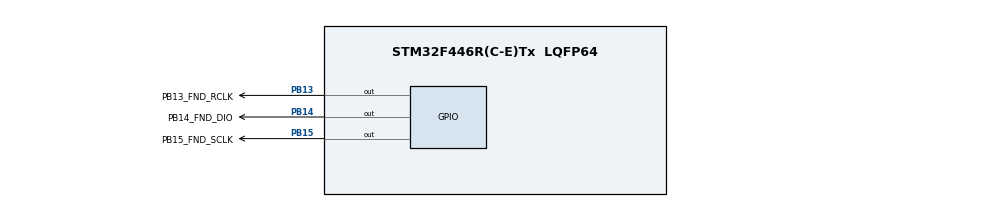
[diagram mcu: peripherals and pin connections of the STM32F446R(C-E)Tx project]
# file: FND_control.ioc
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Mcu.Family=STM32F4
Mcu.Name=STM32F446R(C-E)Tx
Mcu.Package=LQFP64
NVIC.PriorityGroup=NVIC_PRIORITYGROUP_4
PB13.GPIO_Label=PB13_FND_RCLK
PB13.GPIO_ModeDefaultOutputPP=GPIO_MODE_OUTPUT_PP
PB13.GPIO_PuPd=GPIO_PULLUP
PB13.GPIO_Speed=GPIO_SPEED_FREQ_HIGH
PB13.PinState=GPIO_PIN_SET
PB13.Signal=GPIO_Output
PB14.GPIO_Label=PB14_FND_DIO
PB14.GPIO_ModeDefaultOutputPP=GPIO_MODE_OUTPUT_PP
PB14.GPIO_PuPd=GPIO_PULLUP
PB14.GPIO_Speed=GPIO_SPEED_FREQ_HIGH
PB14.PinState=GPIO_PIN_SET
PB14.Signal=GPIO_Output
PB15.GPIO_Label=PB15_FND_SCLK
PB15.GPIO_ModeDefaultOutputPP=GPIO_MODE_OUTPUT_PP
PB15.GPIO_PuPd=GPIO_PULLUP
PB15.GPIO_Speed=GPIO_SPEED_FREQ_HIGH
PB15.PinState=GPIO_PIN_SET
PB15.Signal=GPIO_Output
ProjectManager.HeapSize=0x200
ProjectManager.StackSize=0x400
ProjectManager.TargetToolchain=STM32CubeIDE
RCC.CortexFreq_Value=16000000
RCC.USBFreq_Value=96000000
RCC.VCOOutputFreq_Value=192000000
board=custom

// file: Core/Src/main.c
/* USER CODE BEGIN Header */
/**
  ******************************************************************************
  * @file           : main.c
  * @brief          : Main program body
  ******************************************************************************
  * @attention
  *
  * Copyright (c) 2026 STMicroelectronics.
  * All rights reserved.
  *
  * This software is licensed under terms that can be found in the LICENSE file
  * in the root directory of this software component.
  * If no LICENSE file comes with this software, it is provided AS-IS.
  *
  ******************************************************************************
  */
/* USER CODE END Header */
#include "main.h"

/* USER CODE BEGIN Includes */
#include "FND_controller.h"
/* USER CODE END Includes */

void SystemClock_Config(void);
static void MX_GPIO_Init(void);

int main(void)
{

  /* MCU Configuration--------------------------------------------------------*/

  /* Reset of all peripherals, Initializes the Flash interface and the Systick. */
  HAL_Init();

  /* USER CODE BEGIN Init */

  init_FND();

  /* USER CODE END Init */

  /* Configure the system clock */
  SystemClock_Config();

  /* Initialize all configured peripherals */
  MX_GPIO_Init();

  /* Infinite loop */
  /* USER CODE BEGIN WHILE */
  while (1)
  {
	  // digit2 함수를 이용하여 0부터 99까지 출력
	  /*
	  for (int i = 0; i <= 99; i++)
	  {
		  digit2(i, 0b0001, 50);
	  }
	  */

	  // digit4_replay 함수를 이용하여 0부터 9999까지 출력

	  for (int i = 0; i <= 9999; i++)
	  {
		  //digit4ShowZero_replay(i, 50);
		  digit4_temper(i, 50);
	  }

	  // send_port 함수를 이용하여 GPIO 문자 직접 출력
	  /*
	  send_port(0xC2, 0b1000);
	  send_port(0x8C, 0b0100);
	  send_port(0xF9, 0b0010);
	  send_port(0xC0, 0b0001);
	  */

    /* USER CODE END WHILE */

  }
}

void SystemClock_Config(void)
{
  RCC_OscInitTypeDef RCC_OscInitStruct = {0};
  RCC_ClkInitTypeDef RCC_ClkInitStruct = {0};

  /** Configure the main internal regulator output voltage
  */
  __HAL_RCC_PWR_CLK_ENABLE();
  __HAL_PWR_VOLTAGESCALING_CONFIG(PWR_REGULATOR_VOLTAGE_SCALE3);

  /** Initializes the RCC Oscillators according to the specified parameters
  * in the RCC_OscInitTypeDef structure.
  */
  RCC_OscInitStruct.OscillatorType = RCC_OSCILLATORTYPE_HSI;
  RCC_OscInitStruct.HSIState = RCC_HSI_ON;
  RCC_OscInitStruct.HSICalibrationValue = RCC_HSICALIBRATION_DEFAULT;
  RCC_OscInitStruct.PLL.PLLState = RCC_PLL_NONE;
  if (HAL_RCC_OscConfig(&RCC_OscInitStruct) != HAL_OK)
  {
    Error_Handler();
  }

  /** Initializes the CPU, AHB and APB buses clocks
  */
  RCC_ClkInitStruct.ClockType = RCC_CLOCKTYPE_HCLK|RCC_CLOCKTYPE_SYSCLK
                              |RCC_CLOCKTYPE_PCLK1|RCC_CLOCKTYPE_PCLK2;
  RCC_ClkInitStruct.SYSCLKSource = RCC_SYSCLKSOURCE_HSI;
  RCC_ClkInitStruct.AHBCLKDivider = RCC_SYSCLK_DIV1;
  RCC_ClkInitStruct.APB1CLKDivider = RCC_HCLK_DIV1;
  RCC_ClkInitStruct.APB2CLKDivider = RCC_HCLK_DIV1;

  if (HAL_RCC_ClockConfig(&RCC_ClkInitStruct, FLASH_LATENCY_0) != HAL_OK)
  {
    Error_Handler();
  }
}

static void MX_GPIO_Init(void)
{
  GPIO_InitTypeDef GPIO_InitStruct = {0};

  /* GPIO Ports Clock Enable */
  __HAL_RCC_GPIOB_CLK_ENABLE();

  /*Configure GPIO pin Output Level */
  HAL_GPIO_WritePin(GPIOB, PB13_FND_RCLK_Pin|PB14_FND_DIO_Pin|PB15_FND_SCLK_Pin, GPIO_PIN_SET);

  /*Configure GPIO pins : PB13_FND_RCLK_Pin PB14_FND_DIO_Pin PB15_FND_SCLK_Pin */
  GPIO_InitStruct.Pin = PB13_FND_RCLK_Pin|PB14_FND_DIO_Pin|PB15_FND_SCLK_Pin;
  GPIO_InitStruct.Mode = GPIO_MODE_OUTPUT_PP;
  GPIO_InitStruct.Pull = GPIO_PULLUP;
  GPIO_InitStruct.Speed = GPIO_SPEED_FREQ_HIGH;
  HAL_GPIO_Init(GPIOB, &GPIO_InitStruct);

}

void Error_Handler(void)
{
  __disable_irq();
  while (1)
  {
  }
}
